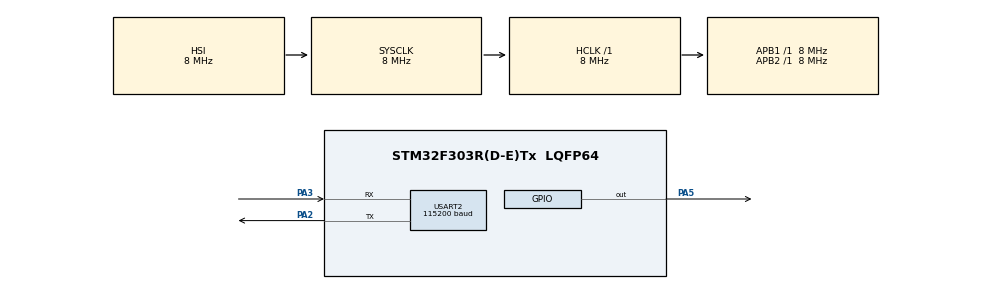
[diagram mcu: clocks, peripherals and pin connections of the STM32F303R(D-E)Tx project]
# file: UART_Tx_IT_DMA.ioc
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Dma.Request0=USART2_TX
Dma.USART2_TX.0.Direction=DMA_MEMORY_TO_PERIPH
Dma.USART2_TX.0.Instance=DMA1_Channel7
Dma.USART2_TX.0.MemDataAlignment=DMA_MDATAALIGN_BYTE
Dma.USART2_TX.0.MemInc=DMA_MINC_ENABLE
Dma.USART2_TX.0.Mode=DMA_CIRCULAR
Dma.USART2_TX.0.PeriphDataAlignment=DMA_PDATAALIGN_BYTE
Dma.USART2_TX.0.PeriphInc=DMA_PINC_DISABLE
Dma.USART2_TX.0.Priority=DMA_PRIORITY_LOW
Mcu.Family=STM32F3
Mcu.Name=STM32F303R(D-E)Tx
Mcu.Package=LQFP64
NVIC.DMA1_Channel7_IRQn=true\:0\:0\:false\:false\:true\:false\:true\:true
NVIC.PriorityGroup=NVIC_PRIORITYGROUP_4
NVIC.USART2_IRQn=true\:0\:0\:false\:false\:true\:true\:true\:true
PA2.Mode=Asynchronous
PA2.Signal=USART2_TX
PA3.Mode=Asynchronous
PA3.Signal=USART2_RX
PA5.Signal=GPIO_Output
ProjectManager.HeapSize=0x200
ProjectManager.StackSize=0x400
ProjectManager.TargetToolchain=STM32CubeIDE
RCC.AHBFreq_Value=8000000
RCC.APB1Freq_Value=8000000
RCC.APB2Freq_Value=8000000
RCC.CortexFreq_Value=8000000
RCC.HSE_VALUE=8000000
RCC.HSI_VALUE=8000000
RCC.LSE_VALUE=32768
RCC.SYSCLKFreq_VALUE=8000000
RCC.USBFreq_Value=16000000
USART2.BaudRate=115200
USART2.VirtualMode-Asynchronous=VM_ASYNC
board=custom

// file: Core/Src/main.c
/* USER CODE BEGIN Header */
/**
  ******************************************************************************
  * @file           : main.c
  * @brief          : Main program body
  ******************************************************************************
  * @attention
  *
  * Copyright (c) 2025 STMicroelectronics.
  * All rights reserved.
  *
  * This software is licensed under terms that can be found in the LICENSE file
  * in the root directory of this software component.
  * If no LICENSE file comes with this software, it is provided AS-IS.
  *
  ******************************************************************************
  */
/* USER CODE END Header */
#include "main.h"

/* USER CODE BEGIN Includes */
#include "stdio.h"
#include "string.h"
/* USER CODE END Includes */

UART_HandleTypeDef huart2;
DMA_HandleTypeDef hdma_usart2_tx;

void SystemClock_Config(void);
static void MX_GPIO_Init(void);
static void MX_DMA_Init(void);
static void MX_USART2_UART_Init(void);

/* USER CODE BEGIN 0 */
volatile int isSent = 1;
volatile int countinterrupt = 0;
volatile int countloop = 0;
uint8_t TxData[10240];
volatile int indx=49;

void HAL_UART_TxHalfCpltCallback(UART_HandleTypeDef *huart)
{
	for(uint32_t i=0; i<5120; i++)
		{
			TxData[i]= indx;
		}
		indx++;
}

void HAL_UART_TxCpltCallback(UART_HandleTypeDef *huart)
{
	for(uint32_t i=5120; i<10240; i++)
	{
		TxData[i]= indx;
	}
	indx++;
	if(indx>=60)
	{
		HAL_UART_DMAStop(&huart2);
	}
	isSent = 1;
	countinterrupt++;
}
/* USER CODE END 0 */

int main(void)
{

  /* MCU Configuration--------------------------------------------------------*/

  /* Reset of all peripherals, Initializes the Flash interface and the Systick. */
  HAL_Init();

  /* Configure the system clock */
  SystemClock_Config();

  /* Initialize all configured peripherals */
  MX_GPIO_Init();
  MX_DMA_Init();
  MX_USART2_UART_Init();
  /* USER CODE BEGIN 2 */
  for (uint32_t i=0; i<10240; i++)
  {
  	  TxData[i] = i&(0xff);
    }

  HAL_UART_Transmit_DMA(&huart2, TxData, 10240);

  /* USER CODE END 2 */

  /* Infinite loop */
  while (1)
  {
	  //if (isSent ==1)
	  	  	  //{
	  //HAL_UART_Transmit(&huart2, TxData, 10240, HAL_MAX_DELAY); // Data transmitted via the normal UART
	  //HAL_UART_Transmit_IT(&huart2, TxData, 10240); //Data Transmitted via the interrupt
	  		  //HAL_UART_Transmit_DMA(&huart2, TxData, 10240);// Data Transmitted via DMA normal mode
	  	  		  //isSent =0;
	  	  	  //}
	  	  	  HAL_GPIO_TogglePin(GPIOA, GPIO_PIN_5);
	  	  	  HAL_Delay(500);
	  	  	  countloop++;
  }
}

void SystemClock_Config(void)
{
  RCC_OscInitTypeDef RCC_OscInitStruct = {0};
  RCC_ClkInitTypeDef RCC_ClkInitStruct = {0};
  RCC_PeriphCLKInitTypeDef PeriphClkInit = {0};

  /** Initializes the RCC Oscillators according to the specified parameters
  * in the RCC_OscInitTypeDef structure.
  */
  RCC_OscInitStruct.OscillatorType = RCC_OSCILLATORTYPE_HSI;
  RCC_OscInitStruct.HSIState = RCC_HSI_ON;
  RCC_OscInitStruct.HSICalibrationValue = RCC_HSICALIBRATION_DEFAULT;
  RCC_OscInitStruct.PLL.PLLState = RCC_PLL_NONE;
  if (HAL_RCC_OscConfig(&RCC_OscInitStruct) != HAL_OK)
  {
    Error_Handler();
  }

  /** Initializes the CPU, AHB and APB buses clocks
  */
  RCC_ClkInitStruct.ClockType = RCC_CLOCKTYPE_HCLK|RCC_CLOCKTYPE_SYSCLK
                              |RCC_CLOCKTYPE_PCLK1|RCC_CLOCKTYPE_PCLK2;
  RCC_ClkInitStruct.SYSCLKSource = RCC_SYSCLKSOURCE_HSI;
  RCC_ClkInitStruct.AHBCLKDivider = RCC_SYSCLK_DIV1;
  RCC_ClkInitStruct.APB1CLKDivider = RCC_HCLK_DIV1;
  RCC_ClkInitStruct.APB2CLKDivider = RCC_HCLK_DIV1;

  if (HAL_RCC_ClockConfig(&RCC_ClkInitStruct, FLASH_LATENCY_0) != HAL_OK)
  {
    Error_Handler();
  }
  PeriphClkInit.PeriphClockSelection = RCC_PERIPHCLK_USART2;
  PeriphClkInit.Usart2ClockSelection = RCC_USART2CLKSOURCE_PCLK1;
  if (HAL_RCCEx_PeriphCLKConfig(&PeriphClkInit) != HAL_OK)
  {
    Error_Handler();
  }
}

static void MX_USART2_UART_Init(void)
{

  huart2.Instance = USART2;
  huart2.Init.BaudRate = 115200;
  huart2.Init.WordLength = UART_WORDLENGTH_8B;
  huart2.Init.StopBits = UART_STOPBITS_1;
  huart2.Init.Parity = UART_PARITY_NONE;
  huart2.Init.Mode = UART_MODE_TX_RX;
  huart2.Init.HwFlowCtl = UART_HWCONTROL_NONE;
  huart2.Init.OverSampling = UART_OVERSAMPLING_16;
  huart2.Init.OneBitSampling = UART_ONE_BIT_SAMPLE_DISABLE;
  huart2.AdvancedInit.AdvFeatureInit = UART_ADVFEATURE_NO_INIT;
  if (HAL_UART_Init(&huart2) != HAL_OK)
  {
    Error_Handler();
  }

}

static void MX_DMA_Init(void)
{

  /* DMA controller clock enable */
  __HAL_RCC_DMA1_CLK_ENABLE();

  /* DMA interrupt init */
  /* DMA1_Channel7_IRQn interrupt configuration */
  HAL_NVIC_SetPriority(DMA1_Channel7_IRQn, 0, 0);
  HAL_NVIC_EnableIRQ(DMA1_Channel7_IRQn);

}

static void MX_GPIO_Init(void)
{
  GPIO_InitTypeDef GPIO_InitStruct = {0};

  /* GPIO Ports Clock Enable */
  __HAL_RCC_GPIOA_CLK_ENABLE();

  /*Configure GPIO pin Output Level */
  HAL_GPIO_WritePin(GPIOA, GPIO_PIN_5, GPIO_PIN_RESET);

  /*Configure GPIO pin : PA5 */
  GPIO_InitStruct.Pin = GPIO_PIN_5;
  GPIO_InitStruct.Mode = GPIO_MODE_OUTPUT_PP;
  GPIO_InitStruct.Pull = GPIO_NOPULL;
  GPIO_InitStruct.Speed = GPIO_SPEED_FREQ_LOW;
  HAL_GPIO_Init(GPIOA, &GPIO_InitStruct);

}

void Error_Handler(void)
{
  __disable_irq();
  while (1)
  {
  }
}
